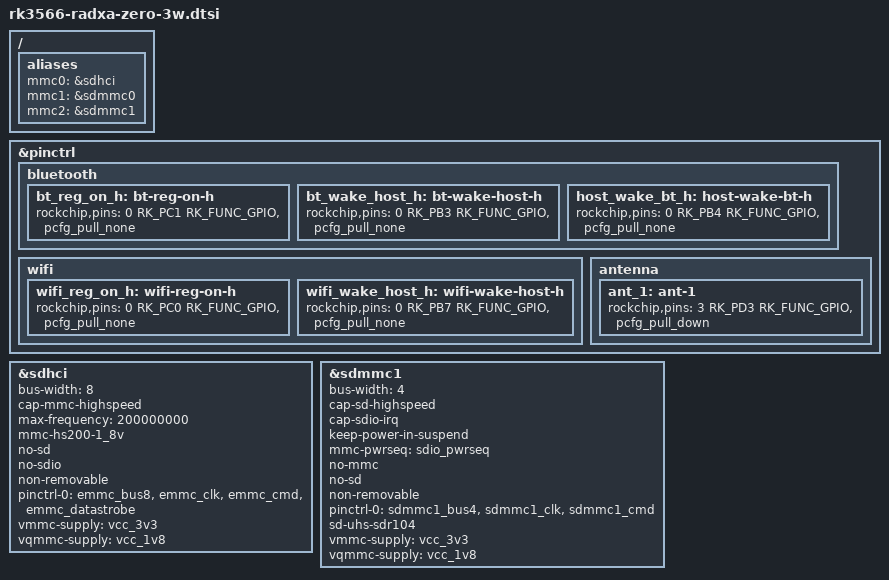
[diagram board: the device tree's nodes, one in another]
// SPDX-License-Identifier: (GPL-2.0+ OR MIT)
/*
 * Common board description for the Radxa ZERO 3W family.
 *
 * The variants differ in the wireless module and therefore in the SDIO
 * power sequence, the UART1 Bluetooth attachment and the antenna switch.
 * Keep those in the per-variant .dts files.
 */

#include "rk3566-radxa-zero-3.dtsi"

/ {
	aliases {
		mmc0 = &sdhci;
		mmc1 = &sdmmc0;
		mmc2 = &sdmmc1;
	};
};

&pinctrl {
	bluetooth {
		bt_reg_on_h: bt-reg-on-h {
			rockchip,pins = <0 RK_PC1 RK_FUNC_GPIO &pcfg_pull_none>;
		};

		bt_wake_host_h: bt-wake-host-h {
			rockchip,pins = <0 RK_PB3 RK_FUNC_GPIO &pcfg_pull_none>;
		};

		host_wake_bt_h: host-wake-bt-h {
			rockchip,pins = <0 RK_PB4 RK_FUNC_GPIO &pcfg_pull_none>;
		};
	};

	wifi {
		wifi_reg_on_h: wifi-reg-on-h {
			rockchip,pins = <0 RK_PC0 RK_FUNC_GPIO &pcfg_pull_none>;
		};

		wifi_wake_host_h: wifi-wake-host-h {
			rockchip,pins = <0 RK_PB7 RK_FUNC_GPIO &pcfg_pull_none>;
		};
	};

	antenna {
		ant_1: ant-1 {
			rockchip,pins = <3 RK_PD3 RK_FUNC_GPIO &pcfg_pull_down>;
		};
	};
};

&sdhci {
	bus-width = <8>;
	cap-mmc-highspeed;
	max-frequency = <200000000>;
	mmc-hs200-1_8v;
	no-sd;
	no-sdio;
	non-removable;
	pinctrl-names = "default";
	pinctrl-0 = <&emmc_bus8 &emmc_clk &emmc_cmd &emmc_datastrobe>;
	vmmc-supply = <&vcc_3v3>;
	vqmmc-supply = <&vcc_1v8>;
	status = "okay";
};

&sdmmc1 {
	bus-width = <4>;
	cap-sd-highspeed;
	cap-sdio-irq;
	keep-power-in-suspend;
	mmc-pwrseq = <&sdio_pwrseq>;
	no-mmc;
	no-sd;
	non-removable;
	pinctrl-names = "default";
	pinctrl-0 = <&sdmmc1_bus4 &sdmmc1_clk &sdmmc1_cmd>;
	sd-uhs-sdr104;
	vmmc-supply = <&vcc_3v3>;
	vqmmc-supply = <&vcc_1v8>;
	status = "okay";
};
